# PIC32MX370F512H device description
Architecture: MIPS; Family: PIC32MX; Series: PIC32MX
Registers are 32-bit, read-write, no defined reset value unless marked. A register's access mark holds for its fields unless they carry their own. Offsets are from the block's base; [hi:lo] are bit positions; {n}, {i} and the like mark numbered series.

## PCACHE
Instances: PCACHE 0x1f884000 in periph2
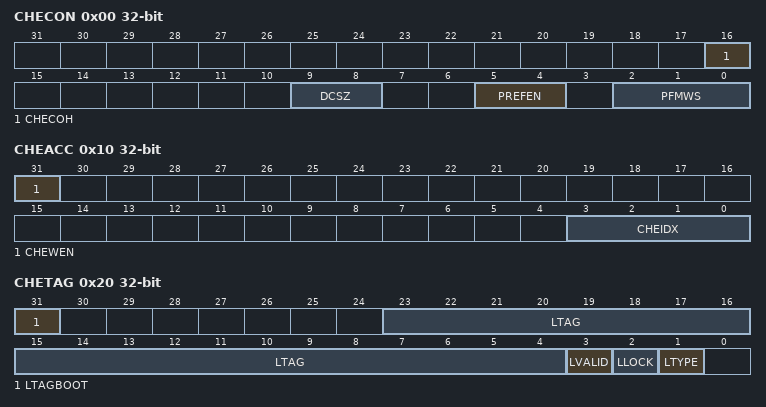
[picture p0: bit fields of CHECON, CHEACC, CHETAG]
0x00 CHECON — Cache Control Register
  [16] CHECOH — Cache Coherency Setting on a PFM Program Cycle bit
    1=Invalidate all data and instruction lines; 0=Invalidate all data lines and instruction lines that are not locked
  [9:8] DCSZ — Data Cache Size in Lines bits
    3=Enable data caching with a size of 4 Lines; 2=Enable data caching with a size of 2 Lines; 1=Enable data caching with a size of 1 Line; 0=Disable data caching
  [5:4] PREFEN — Predictive Prefetch Enable bits
    3=Enable predictive prefetch for both cacheable and non-cacheable regions; 2=Enable predictive prefetch for non-cacheable regions only; 1=Enable predictive prefetch for cacheable regions only; 0=Disable predictive prefetch
  [2:0] PFMWS — PFM Access Time Defined in Terms of SYSLK Wait States bits
    7=Seven Wait states; 6=Six Wait states; 5=Five Wait states; 4=Four Wait states; 3=Three Wait states; 2=Two Wait states; 1=One Wait state; 0=Zero Wait state
0x10 CHEACC — Cache Access Register
  [31] CHEWEN — Cache Access Enable bits for registers CHETAG
    1=The cache line selected by CHEIDX(3:0) is writeable; 0=The cache line selected by CHEIDX(3:0) is not writeable
  [3:0] CHEIDX — Cache Line Index bits
    {v}=Select cache line {v} for reading or writing (v=0..15)
0x20 CHETAG — Cache TAG Register
  [31] LTAGBOOT — Line TAG Address Boot bit
    1=The line is in the 0x1D000000 (physical) area of memory; 0=The line is in the 0x1FC00000 (physical) area of memory
  [23:4] LTAG
  [3] LVALID — Line Valid bit
    1=The line is valid and is compared to the physical address for hit detection; 0=The line is not valid and is not compared to the physical address for hit detection
  [2] LLOCK — Line Lock bit
    1=The line is locked and will not be replaced; 0=The line is not locked and can be replaced
  [1] LTYPE — Line Type bit
    1=The line caches instruction words; 0=The line caches data words
0x30 CHEMSK — Cache TAG Mask Register
  [15:5] LMASK — Line Mask bits
    1=Enables mask logic to force a match on the corresponding bit position in the LTAG(19:0) bits (CHETAG(23:4)) and the physical address; 0=Only writeable for values of CHEIDX(3:0) bits (CHEACC(3:0)) equal to 0x0A and 0x0B. Disables mask logic.
{0x40+0x10*i} CHEW{i} (i=0..3) — Cache Word {i}
0x80 CHELRU — Cache LRU Register
  [24:0] CHELRU
0x90 CHEHIT ro — Cache Hit Statistics Register
0xA0 CHEMIS ro — Cache Miss Statistics Register
0xC0 CHEPFABT ro — Prefetch Cache Abort Statistics Register

## RCON
Instances: RCON 0x1f80f600 in periph1
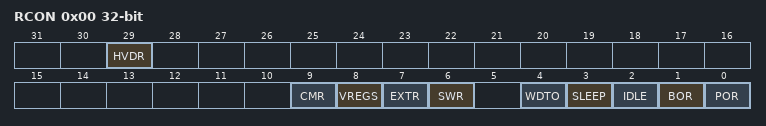
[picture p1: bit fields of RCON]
0x00 RCON — Reset Control Register
  [29] HVDR — High Voltage Detect Reset Flag bit
    1=High Voltage Detect (HVD) Reset has occurred; 0=HVD Reset has not occurred
  [9] CMR — Configuration Mismatch Reset Flag bit
    1=Configuration mismatch Reset has occurred; 0=Configuration mismatch Reset has not occurred
  [8] VREGS — Voltage Regulator Standby Enable bit
    1=Regulator is enabled and is on during Sleep mode; 0=Regulator is set to Stand-by Tracking mode
  [7] EXTR — External Reset Pin Flag bit
    1=Master Clear (pin) Reset has occurred; 0=Master Clear (pin) Reset has not occurred
  [6] SWR — Software Reset Flag bit
    1=Software Reset was executed; 0=Software Reset as not executed
  [4] WDTO — Watchdog Timer Time-out Flag bit
    1=WDT Time-out has occurred; 0=WDT Time-out has not occurred
  [3] SLEEP — Wake From Sleep Flag bit
    1=Device was in Sleep mode; 0=Device was not in Sleep mode
  [2] IDLE — Wake From Idle Flag bit
    1=Device was in Idle mode; 0=Device was not in Idle mode
  [1] BOR — Brown-out Reset Flag bit
    1=Brown-out Reset has occurred; 0=Brown-out Reset has not occurred
  [0] POR — Power-on Reset Flag bit
    1=Power-on Reset has occurred; 0=Power-on Reset has not occurred
0x10 RSWRST — Software Reset Register
  [0] SWRST — Software Reset Trigger bit
    1=Enable software Reset event; 0=No effect

## Notices in the file
Copyright (c) 2019 Microchip Technology Inc.
SPDX-License-Identifier: Apache-2.0
Licensed under the Apache License, Version 2.0 (the "License");
you may not use this file except in compliance with the License.
You may obtain a copy of the License at
http://www.apache.org/licenses/LICENSE-2.0
Unless required by applicable law or agreed to in writing, software
distributed under the License is distributed on an "AS IS" BASIS,
WITHOUT WARRANTIES OR CONDITIONS OF ANY KIND, either express or implied.
See the License for the specific language governing permissions and
limitations under the License.
